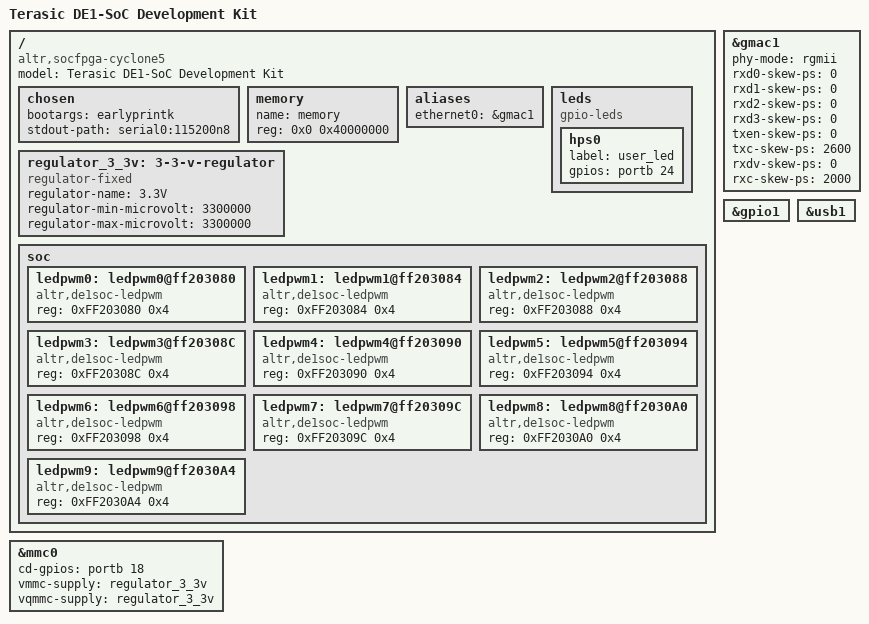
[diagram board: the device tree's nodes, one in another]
/*
 *  Copyright (C) 2012 Altera Corporation <www.altera.com>
 *  Copyright (C) 2017 Gerhard Engleder <engleder.gerhard@gmail.com>
 *
 * This program is free software; you can redistribute it and/or modify
 * it under the terms of the GNU General Public License as published by
 * the Free Software Foundation; either version 2 of the License, or
 * (at your option) any later version.
 *
 * This program is distributed in the hope that it will be useful,
 * but WITHOUT ANY WARRANTY; without even the implied warranty of
 * MERCHANTABILITY or FITNESS FOR A PARTICULAR PURPOSE.  See the
 * GNU General Public License for more details.
 *
 * You should have received a copy of the GNU General Public License
 * along with this program.  If not, see <http://www.gnu.org/licenses/>.
 */

#include "socfpga_cyclone5.dtsi"

/ {
	model = "Terasic DE1-SoC Development Kit";
	compatible = "altr,socfpga-cyclone5", "altr,socfpga";

	chosen {
		bootargs = "earlyprintk";
		stdout-path = "serial0:115200n8";
	};

	memory {
		name = "memory";
		device_type = "memory";
		reg = <0x0 0x40000000>; /* 1GB */
	};

	aliases {
		/* this allow the ethaddr uboot environmnet variable contents
		 * to be added to the gmac1 device tree blob.
		 */
		ethernet0 = &gmac1;
	};

	leds {
		compatible = "gpio-leds";
		hps0 {
			label = "user_led";
			gpios = <&portb 24 0>;
		};
	};

	regulator_3_3v: 3-3-v-regulator {
		compatible = "regulator-fixed";
		regulator-name = "3.3V";
		regulator-min-microvolt = <3300000>;
		regulator-max-microvolt = <3300000>;
	};
};

&gmac1 {
	status = "okay";
	phy-mode = "rgmii";

	rxd0-skew-ps = <0>;
	rxd1-skew-ps = <0>;
	rxd2-skew-ps = <0>;
	rxd3-skew-ps = <0>;
	txen-skew-ps = <0>;
	txc-skew-ps = <2600>;
	rxdv-skew-ps = <0>;
	rxc-skew-ps = <2000>;
};

&gpio1 {
	status = "okay";
};

&mmc0 {
	cd-gpios = <&portb 18 0>;
	vmmc-supply = <&regulator_3_3v>;
	vqmmc-supply = <&regulator_3_3v>;
	status = "okay";
};

&usb1 {
	status = "okay";
};

/ {
	soc {
		ledpwm0: ledpwm0@ff203080 {
			compatible = "altr,de1soc-ledpwm";
			reg = <0xFF203080 0x4>;
		};
		ledpwm1: ledpwm1@ff203084 {
			compatible = "altr,de1soc-ledpwm";
			reg = <0xFF203084 0x4>;
		};
		ledpwm2: ledpwm2@ff203088 {
			compatible = "altr,de1soc-ledpwm";
			reg = <0xFF203088 0x4>;
		};
		ledpwm3: ledpwm3@ff20308C {
			compatible = "altr,de1soc-ledpwm";
			reg = <0xFF20308C 0x4>;
		};
		ledpwm4: ledpwm4@ff203090 {
			compatible = "altr,de1soc-ledpwm";
			reg = <0xFF203090 0x4>;
		};
		ledpwm5: ledpwm5@ff203094 {
			compatible = "altr,de1soc-ledpwm";
			reg = <0xFF203094 0x4>;
		};
		ledpwm6: ledpwm6@ff203098 {
			compatible = "altr,de1soc-ledpwm";
			reg = <0xFF203098 0x4>;
		};
		ledpwm7: ledpwm7@ff20309C {
			compatible = "altr,de1soc-ledpwm";
			reg = <0xFF20309C 0x4>;
		};
		ledpwm8: ledpwm8@ff2030A0 {
			compatible = "altr,de1soc-ledpwm";
			reg = <0xFF2030A0 0x4>;
		};
		ledpwm9: ledpwm9@ff2030A4 {
			compatible = "altr,de1soc-ledpwm";
			reg = <0xFF2030A4 0x4>;
		};
	};
};
